AUTOSAR XML (schema 314)
package /ComponentType
  internal behavior Sa_MtrVel_InternalBehavior: component=Sa_MtrVel
    timing event MtrVel_Init1_InitEvent: start-on-event=MtrVel_Init1, period=0
    timing event TMT_MtrVel_Per1: start-on-event=MtrVel_Per1, period=0.002
    timing event TMT_MtrVel_Per2: start-on-event=MtrVel_Per2, period=0.004
    port-api-options:
      enable-take-address=false, indirect-api=false, port=AsstAssemPol
      enable-take-address=false, indirect-api=false, port=CRFMotorVel
      enable-take-address=false, indirect-api=false, port=HandwheelVel
      enable-take-address=false, indirect-api=false, port=HwVelValid
      enable-take-address=false, indirect-api=false, port=MRFMotorVel
      enable-take-address=false, indirect-api=false, port=MRFMotorVelUnfiltered
      enable-take-address=false, indirect-api=false, port=MtrVel_Per1_CP0
      enable-take-address=false, indirect-api=false, port=NxtrDiagMgr
      enable-take-address=false, indirect-api=false, port=SysCDiagHandWheelVel
      enable-take-address=false, indirect-api=false, port=SysCDiagMtrVelMRF
      enable-take-address=false, indirect-api=false, port=SysCHandwheelVel
      enable-take-address=false, indirect-api=false, port=SysCMotorVelMRF
      enable-take-address=false, indirect-api=false, port=VehicleSpeed
    runnable MtrVel_Init1
    runnable MtrVel_Per1
      data read access READ_AsstAssemPol_Cnt_s08: data-element=AsstAssemPol.Cnt_s08
      data read access READ_VehicleSpeed_Kph_f32: data-element=VehicleSpeed.Kph_f32
      7 x data write access:
        WRITE_CRFMotorVel_MtrRadpS_f32: data-element=CRFMotorVel.MtrRadpS_f32
        WRITE_HandwheelVel_HwRadpS_f32: data-element=HandwheelVel.HwRadpS_f32
        WRITE_HwVelValid_Cnt_lgc: data-element=HwVelValid.Cnt_lgc
        WRITE_MRFMotorVel_MtrRadpS_f32: data-element=MRFMotorVel.MtrRadpS_f32
        WRITE_MRFMotorVelUnfiltered_MtrRadpS_f32: data-element=MRFMotorVelUnfiltered.MtrRadpS_f32
        WRITE_SysCHandwheelVel_HwRadpS_f32: data-element=SysCHandwheelVel.HwRadpS_f32
        WRITE_SysCMotorVelMRF_MtrRadpS_f32: data-element=SysCMotorVelMRF.MtrRadpS_f32
      sync call SC_MtrVel_Per1_CP0_CheckpointReached: operation=MtrVel_Per1_CP0.CheckpointReached, timeout=0
      sync call SC_NxtrDiagMgr_GetNTCFailed: operation=NxtrDiagMgr.GetNTCFailed, timeout=0
    runnable MtrVel_Per2
      data read access READ_SysCDiagHandWheelVel_HwRadpS_f32: data-element=SysCDiagHandWheelVel.HwRadpS_f32
      data read access READ_SysCDiagMtrVelMRF_MtrRadpS_f32: data-element=SysCDiagMtrVelMRF.MtrRadpS_f32
      sync call SC_NxtrDiagMgr_SetNTCStatus: operation=NxtrDiagMgr.SetNTCStatus, timeout=0
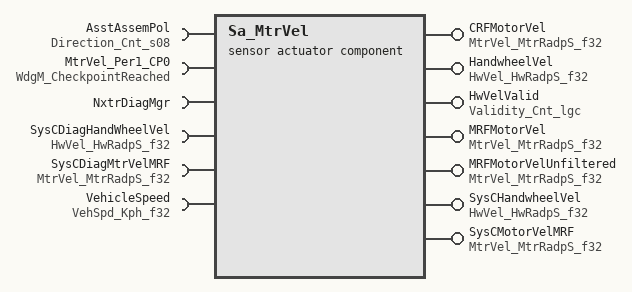
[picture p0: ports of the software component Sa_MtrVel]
  sensor actuator software component type Sa_MtrVel
    7 x provide port:
      CRFMotorVel: unqueued-sender-com-spec{data-element=MtrRadpS_f32, can-invalidate=false, init-value=D_FLOATZERO_ULS_F32}, provided-interface=MtrVel_MtrRadpS_f32
      HandwheelVel: unqueued-sender-com-spec{data-element=HwRadpS_f32, can-invalidate=false, init-value=D_FLOATZERO_ULS_F32}, provided-interface=HwVel_HwRadpS_f32
      HwVelValid: unqueued-sender-com-spec{data-element=Cnt_lgc, can-invalidate=false, init-value=D_FALSE_CNT_LGC}, provided-interface=Validity_Cnt_lgc
      MRFMotorVel: unqueued-sender-com-spec{data-element=MtrRadpS_f32, can-invalidate=false, init-value=D_FLOATZERO_ULS_F32}, provided-interface=MtrVel_MtrRadpS_f32
      MRFMotorVelUnfiltered: unqueued-sender-com-spec{data-element=MtrRadpS_f32, can-invalidate=false, init-value=D_FLOATZERO_ULS_F32}, provided-interface=MtrVel_MtrRadpS_f32
      SysCHandwheelVel: unqueued-sender-com-spec{data-element=HwRadpS_f32, can-invalidate=false, init-value=D_FLOATZERO_ULS_F32}, provided-interface=HwVel_HwRadpS_f32
      SysCMotorVelMRF: unqueued-sender-com-spec{data-element=MtrRadpS_f32, can-invalidate=false, init-value=D_FLOATZERO_ULS_F32}, provided-interface=MtrVel_MtrRadpS_f32
    6 x require port:
      AsstAssemPol: unqueued-receiver-com-spec{data-element=Cnt_s08, init-value=D_ZERO_CNT_S8}, required-interface=Direction_Cnt_s08
      MtrVel_Per1_CP0: client-com-spec=CheckpointReached, required-interface=WdgM_CheckpointReached
      NxtrDiagMgr: required-com-specs=[GetNTCActive, GetNTCFailed, GetNTCStatus, SetNTCStatus], required-interface=NxtrDiagMgr
      SysCDiagHandWheelVel: unqueued-receiver-com-spec{data-element=HwRadpS_f32, init-value=D_FLOATZERO_ULS_F32}, required-interface=HwVel_HwRadpS_f32
      SysCDiagMtrVelMRF: unqueued-receiver-com-spec{data-element=MtrRadpS_f32, init-value=D_FLOATZERO_ULS_F32}, required-interface=MtrVel_MtrRadpS_f32
      VehicleSpeed: unqueued-receiver-com-spec{data-element=Kph_f32, init-value=D_FLOATZERO_ULS_F32}, required-interface=VehSpd_Kph_f32
  swc implementation Sa_MtrVel_Implementation: behavior=Sa_MtrVel_InternalBehavior
    code-descriptors:
      code Code: type=SRC
